# adc_revb register map
Registers are 32-bit, read-write, no defined reset value unless marked. A register's access mark holds for its fields unless they carry their own. Offsets are from the block's base; lines under a group give offsets from that group; [hi:lo] are bit positions; {n}, {i} and the like mark numbered series; 'fields as' and 'values as' point back to an identical list; <NAME> marks a mode.

## Memory map
0x40034000 ADC size 0x1000 — Inter-Integrated Circuit.

## Interrupts
20 ADC — ADC IRQ

## ADC — Inter-Integrated Circuit.
Base 0x40034000
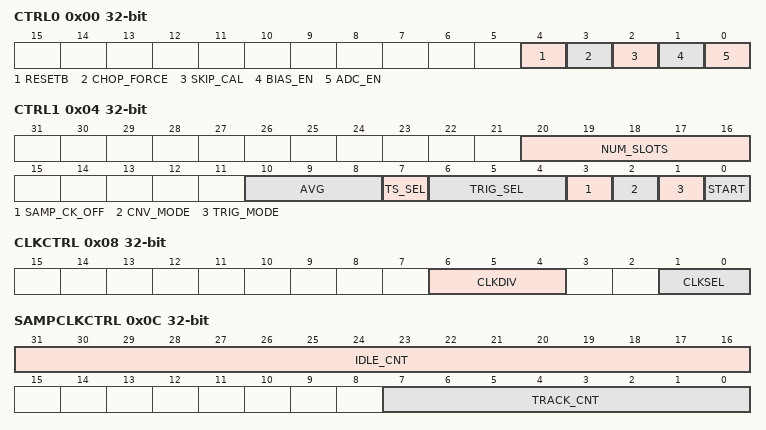
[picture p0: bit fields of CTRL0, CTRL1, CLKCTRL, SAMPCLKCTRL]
0x00 CTRL0 — Control Register 0.
  [4] RESETB — Reset ADC.
    0=reset ADC; 1=activate ADC
  [3] CHOP_FORCE — Chop Force Control.
    0=dis (Do not force chop mode.); 1=en (Force chop Mode.)
  [2] SKIP_CAL — Skip Calibration Enable.
    0=no_skip (Do not skip calibration.); 1=Skip calibration
  [1] BIAS_EN — Bias Enable.
    0=dis (Disable Bias.); 1=en (Enable Bias.)
  [0] ADC_EN — ADC Enable.
    0=dis (Disable ADC.); 1=en (enable ADC.)
0x04 CTRL1 — Control Register 1.
  [20:16] NUM_SLOTS — Number of slots enabled for the conversion sequence
  [10:8] AVG — Number of samples to average for each output data code.
    0=1 Sample per output code; 1=2 Samples per output code; 2=4 Samples per output code; 3=8 Samples per output code; 4=16 Samples per output code; 5=32 Samples per output code
  [7] TS_SEL — Temp sensor select.
    0=dis (Temp sensor is not one of the slots in the sequence.); 1=en (Temp sensor is one of the slots in the sequence.)
  [6:4] TRIG_SEL — Hardware trigger source select.
  [3] SAMP_CK_OFF — Sample clock off control.
    0=always (Sample clock always generated.); 1=cnv_only (Sample clock generated only when converting.)
  [2] CNV_MODE — Conversion mode control.
    0=atomic (Do one conversion sequence.); 1=continuous (Do continuous conversion sequences.)
  [1] TRIG_MODE — Trigger mode control.
    0=software trigger mode; 1=hardware trigger mode
  [0] START — Start conversion control.
    0=Stop conversions; 1=Start conversions
0x08 CLKCTRL — Clock Control Register.
  [6:4] CLKDIV — Clock divider control.
    0=DIV2 (Divide by 2.); 1=DIV4 (Divide by 4.); 2=DIV8 (Divide by 8.); 3=DIV16 (Divide by 16.); 4=DIV1 (Divide by 1.)
  [1:0] CLKSEL — Clock source select.
    0=HCLK (Select HCLK.); 1=CLK_ADC0 (Select CLK_ADC0.); 2=CLK_ADC1 (Select CLK_ADC1.); 3=CLK_ADC2 (Select CLK_ADC2.)
0x0C SAMPCLKCTRL — Sample Clock Control Register.
  [31:16] IDLE_CNT — Number of cycles for SAMPLE_CLK low time.
  [7:0] TRACK_CNT — Number of cycles for SAMPLE_CLK high time.
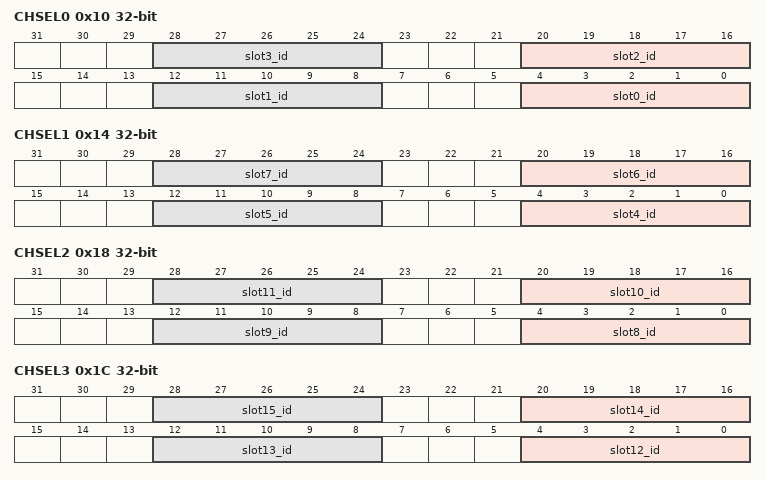
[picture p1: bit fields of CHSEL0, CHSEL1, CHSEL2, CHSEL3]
0x10 CHSEL0 — Channel Select Register 0.
  [8n+4:8n] slot{n}_id (n=0..3) — channel assignment for slot {n}.
0x14 CHSEL1 — Channel Select Register 1.
  [8n-28:8n-32] slot{n}_id (n=4..7) — channel assignment for slot {n}.
0x18 CHSEL2 — Channel Select Register 2.
  [8n-60:8n-64] slot{n}_id (n=8..11) — channel assignment for slot {n}.
0x1C CHSEL3 — Channel Select Register 3.
  [8n-92:8n-96] slot{n}_id (n=12..15) — channel assignment for slot {n}.
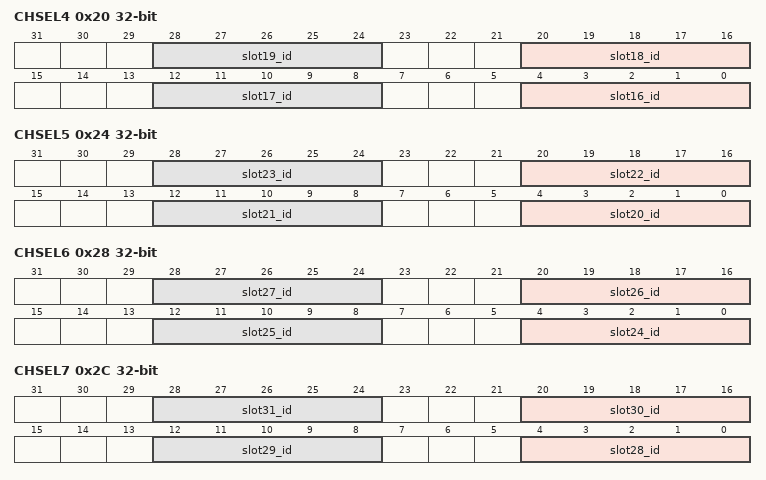
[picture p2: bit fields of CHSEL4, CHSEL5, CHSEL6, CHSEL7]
0x20 CHSEL4 — Channel Select Register 4.
  [8n-124:8n-128] slot{n}_id (n=16..19) — channel assignment for slot {n}.
0x24 CHSEL5 — Channel Select Register 5.
  [8n-156:8n-160] slot{n}_id (n=20..23) — channel assignment for slot {n}.
0x28 CHSEL6 — Channel Select Register 6.
  [8n-188:8n-192] slot{n}_id (n=24..27) — channel assignment for slot {n}.
0x2C CHSEL7 — Channel Select Register 7.
  [8n-220:8n-224] slot{n}_id (n=28..31) — channel assignment for slot {n}.
0x30 RESTART — Restart Count Control Register
  [15:0] CNT — Number of sample periods to skip before restarting a continuous mode sequence
0x3C DATAFMT — Channel Data Format Register
  [31:0] MODE — Data format control
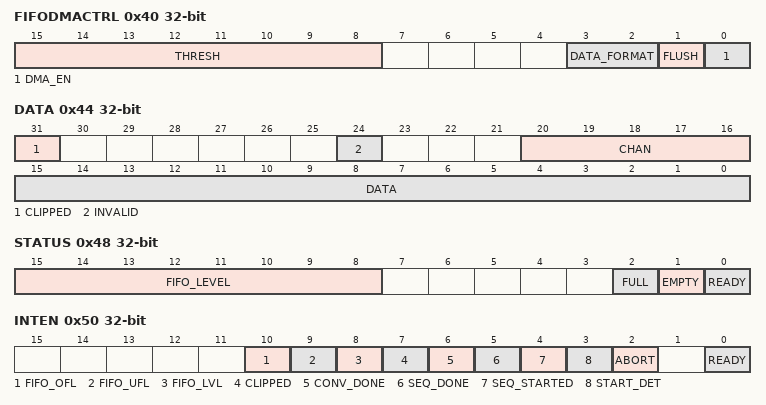
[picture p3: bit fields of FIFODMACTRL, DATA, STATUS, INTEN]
0x40 FIFODMACTRL — FIFO and DMA control
  [15:8] THRESH — FIFO Threshold. These bits define the FIFO interrupt threshold.
  [3:2] DATA_FORMAT — DATA format control.
    0=data_status (Data and Status in FIFO.); 1=data_only (Only Data in FIFO.); 2=raw_data_only (Only Raw Data in FIFO.)
  [1] FLUSH — FIFO Flush.
    0=Normal FIFO operation; 1=Flush FIFO
  [0] DMA_EN — DMA Enable.
    0=dis (Disable DMA.); 1=en (Enable DMA.)
0x44 DATA ro — Data Register (FIFO).
  [31] CLIPPED — Clipped status for the data.
  [24] INVALID — Invalid status for the data.
  [20:16] CHAN — Channel for the data.
  [15:0] DATA — Conversion data.
0x48 STATUS ro
  [15:8] FIFO_LEVEL — Number of entries in FIFO available to read
  [2] FULL — FIFO full
  [1] EMPTY — FIFO Empty
  [0] READY — Indication that the ADC is in ON power state
0x4C CHSTATUS — Channel Status
  [31:0] CLIPPED
0x50 INTEN — Interrupt Enable Register.
  [10] FIFO_OFL
  [9] FIFO_UFL
  [8] FIFO_LVL
  [7] CLIPPED
  [6] CONV_DONE
  [5] SEQ_DONE
  [4] SEQ_STARTED
  [3] START_DET — Conversion start is detected.
  [2] ABORT — Conversion start is aborted.
  [0] READY — ADC is ready.
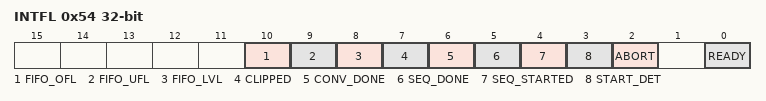
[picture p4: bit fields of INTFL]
0x54 INTFL — Interrupt Flags Register.
  [10] FIFO_OFL write-1-clears
  [9] FIFO_UFL write-1-clears
  [8] FIFO_LVL write-1-clears
  [7] CLIPPED write-1-clears
  [6] CONV_DONE write-1-clears
  [5] SEQ_DONE write-1-clears
  [4] SEQ_STARTED write-1-clears
  [3] START_DET write-1-clears — Conversion start is detected.
  [2] ABORT write-1-clears — Conversion start is aborted.
  [0] READY write-1-clears — ADC is ready.
0x60 SFRADDROFFSET — SFR Address Offset Register
  [7:0] OFFSET — Address Offset for SAR Digital
0x64 SFRADDR — SFR Address Register
  [7:0] ADDR — Address to SAR Digital
0x68 SFRWRDATA — SFR Write Data Register
  [7:0] DATA — DATA to SAR Digital
0x6C SFRRDDATA ro — SFR Read Data Register
  [7:0] DATA — DATA from SAR Digital
0x70 SFRSTATUS ro
  [0] NACK — NACK status for SAR Digital SFR communication
